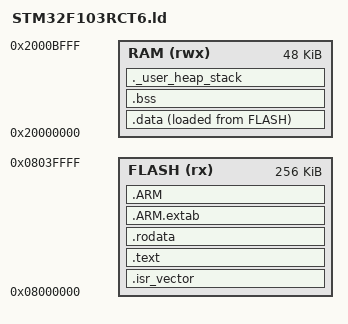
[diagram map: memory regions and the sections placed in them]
/* =========================================================================
 *  链接脚本：STM32F103RCT6
 *  Flash: 256KB @ 0x08000000   RAM: 48KB @ 0x20000000
 *  由 build.py 通过 -T 引用。
 * ========================================================================= */
ENTRY(Reset_Handler)

_estack = 0x2000C000;    /* RAM 末尾 (0x20000000 + 48KB) */
_Min_Heap_Size  = 0x1000;  /* 最小堆 4KB */
_Min_Stack_Size = 0x0800;  /* 最小栈 2KB */

MEMORY
{
  FLASH (rx)  : ORIGIN = 0x08000000, LENGTH = 256K
  RAM   (rwx) : ORIGIN = 0x20000000, LENGTH = 48K
}

_HeapLimit = _estack - _Min_Stack_Size;

SECTIONS
{
  .isr_vector :
  {
    . = ALIGN(4);
    KEEP(*(.isr_vector))
    . = ALIGN(4);
  } > FLASH

  .text :
  {
    . = ALIGN(4);
    *(.text)
    *(.text.*)
    *(.glue_7)
    *(.glue_7t)
    *(.eh_frame)
    KEEP(*(.init))
    KEEP(*(.fini))
    . = ALIGN(4);
    _etext = .;
  } > FLASH

  .rodata :
  {
    . = ALIGN(4);
    *(.rodata)
    *(.rodata.*)
    . = ALIGN(4);
  } > FLASH

  .ARM.extab :
  {
    *(.ARM.extab* .gnu.linkonce.armextab.*)
  } > FLASH

  .ARM :
  {
    __exidx_start = .;
    *(.ARM.exidx*)
    __exidx_end = .;
  } > FLASH

  _sidata = LOADADDR(.data);

  .data :
  {
    . = ALIGN(4);
    _sdata = .;
    *(.data)
    *(.data.*)
    . = ALIGN(4);
    _edata = .;
  } > RAM AT > FLASH

  .bss :
  {
    . = ALIGN(4);
    _sbss = .;
    *(.bss)
    *(.bss.*)
    *(COMMON)
    . = ALIGN(4);
    _ebss = .;
  } > RAM

  ._user_heap_stack :
  {
    . = ALIGN(8);
    PROVIDE ( end = . );
    PROVIDE ( _end = . );
    . = . + _Min_Heap_Size;
    . = . + _Min_Stack_Size;
    . = ALIGN(8);
  } > RAM

  /DISCARD/ :
  {
    *(.note.*)
    *(.comment)
  }
}
